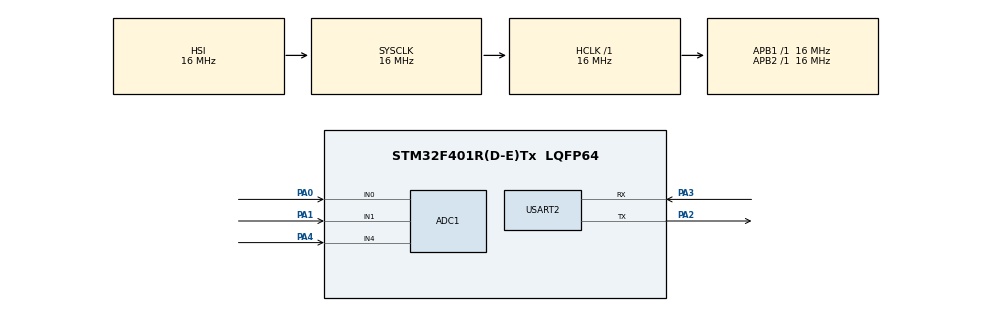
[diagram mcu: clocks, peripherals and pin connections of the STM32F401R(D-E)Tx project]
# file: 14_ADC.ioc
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ADC1.Channel-0\#ChannelRegularConversion=ADC_CHANNEL_0
ADC1.ClockPrescaler=ADC_CLOCK_SYNC_PCLK_DIV4
ADC1.NbrOfConversionFlag=1
ADC1.Rank-0\#ChannelRegularConversion=1
ADC1.SamplingTime-0\#ChannelRegularConversion=ADC_SAMPLETIME_3CYCLES
ADC1.master=1
Mcu.Family=STM32F4
Mcu.Name=STM32F401R(D-E)Tx
Mcu.Package=LQFP64
NVIC.PriorityGroup=NVIC_PRIORITYGROUP_4
PA0-WKUP.Signal=ADCx_IN0
PA1.Signal=ADCx_IN1
PA13.Mode=Serial_Wire
PA13.Signal=SYS_JTMS-SWDIO
PA14.Mode=Serial_Wire
PA14.Signal=SYS_JTCK-SWCLK
PA2.Mode=Asynchronous
PA2.Signal=USART2_TX
PA3.Mode=Asynchronous
PA3.Signal=USART2_RX
PA4.Signal=ADCx_IN4
ProjectManager.HeapSize=0x200
ProjectManager.StackSize=0x400
ProjectManager.TargetToolchain=STM32CubeIDE
RCC.AHBFreq_Value=16000000
RCC.APB1Freq_Value=16000000
RCC.APB2Freq_Value=16000000
RCC.CortexFreq_Value=16000000
RCC.HSE_VALUE=25000000
RCC.HSI_VALUE=16000000
RCC.LSE_VALUE=32768
RCC.SYSCLKFreq_VALUE=16000000
RCC.VCOOutputFreq_Value=192000000
SH.ADCx_IN0.0=ADC1_IN0,IN0
SH.ADCx_IN1.0=ADC1_IN1,IN1
SH.ADCx_IN4.0=ADC1_IN4,IN4
USART2.VirtualMode=VM_ASYNC
board=custom

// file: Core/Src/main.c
/* USER CODE BEGIN Header */
/**
  ******************************************************************************
  * @file           : main.c
  * @brief          : Main program body
  ******************************************************************************
  * @attention
  *
  * Copyright (c) 2023 STMicroelectronics.
  * All rights reserved.
  *
  * This software is licensed under terms that can be found in the LICENSE file
  * in the root directory of this software component.
  * If no LICENSE file comes with this software, it is provided AS-IS.
  *
  ******************************************************************************
  */
/* USER CODE END Header */
#include "main.h"
#include "adc.h"
#include "usart.h"
#include "gpio.h"

/* USER CODE BEGIN Includes */
#include <stdio.h>
#include <string.h>
/* USER CODE END Includes */

/* USER CODE BEGIN PV */
uint32_t adc[3];
/* USER CODE END PV */

void SystemClock_Config(void);
/* USER CODE BEGIN PFP */
int __io_putchar(int ch){
	 HAL_UART_Transmit(&huart2,(const uint8_t *)&ch, 1, HAL_MAX_DELAY);
	 return ch;
}
/* USER CODE END PFP */

int main(void)
{

  /* MCU Configuration--------------------------------------------------------*/

  /* Reset of all peripherals, Initializes the Flash interface and the Systick. */
  HAL_Init();

  /* Configure the system clock */
  SystemClock_Config();

  /* Initialize all configured peripherals */
  MX_GPIO_Init();
  MX_ADC1_Init();
  MX_USART2_UART_Init();

  /* Infinite loop */
  /* USER CODE BEGIN WHILE */
  while (1)
  {
	  adc[0] = AnalogRead(0);
	  adc[1] = AnalogRead(1);
	  adc[2] = AnalogRead(4);

	  printf("ADC[0] = %u    ADC[1] = %u   ADC[4] = %u   \n\r",adc[0],adc[1],adc[2]);
	  HAL_Delay(400);

    /* USER CODE END WHILE */

  }
}

void SystemClock_Config(void)
{
  RCC_OscInitTypeDef RCC_OscInitStruct = {0};
  RCC_ClkInitTypeDef RCC_ClkInitStruct = {0};

  /** Configure the main internal regulator output voltage
  */
  __HAL_RCC_PWR_CLK_ENABLE();
  __HAL_PWR_VOLTAGESCALING_CONFIG(PWR_REGULATOR_VOLTAGE_SCALE2);

  /** Initializes the RCC Oscillators according to the specified parameters
  * in the RCC_OscInitTypeDef structure.
  */
  RCC_OscInitStruct.OscillatorType = RCC_OSCILLATORTYPE_HSI;
  RCC_OscInitStruct.HSIState = RCC_HSI_ON;
  RCC_OscInitStruct.HSICalibrationValue = RCC_HSICALIBRATION_DEFAULT;
  RCC_OscInitStruct.PLL.PLLState = RCC_PLL_NONE;
  if (HAL_RCC_OscConfig(&RCC_OscInitStruct) != HAL_OK)
  {
    Error_Handler();
  }

  /** Initializes the CPU, AHB and APB buses clocks
  */
  RCC_ClkInitStruct.ClockType = RCC_CLOCKTYPE_HCLK|RCC_CLOCKTYPE_SYSCLK
                              |RCC_CLOCKTYPE_PCLK1|RCC_CLOCKTYPE_PCLK2;
  RCC_ClkInitStruct.SYSCLKSource = RCC_SYSCLKSOURCE_HSI;
  RCC_ClkInitStruct.AHBCLKDivider = RCC_SYSCLK_DIV1;
  RCC_ClkInitStruct.APB1CLKDivider = RCC_HCLK_DIV1;
  RCC_ClkInitStruct.APB2CLKDivider = RCC_HCLK_DIV1;

  if (HAL_RCC_ClockConfig(&RCC_ClkInitStruct, FLASH_LATENCY_0) != HAL_OK)
  {
    Error_Handler();
  }
}

void Error_Handler(void)
{
  __disable_irq();
  while (1)
  {
  }
}
